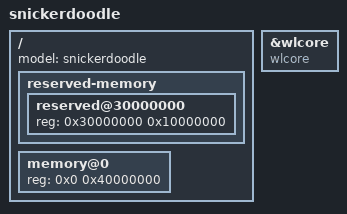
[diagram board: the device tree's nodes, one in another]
/**
 * Copyright (c) 2016 krtkl inc.
 *
 * snickerdoodle base device tree source
 *
 * This program is free software; you can redistribute it and/or modify it
 * under the terms of the GNU General Public License version 2 as published by
 * the Free Software Foundation.
 */

/dts-v1/;
/include/ "snickerdoodle.dtsi"
/include/ "uio.dtsi"

/ {
	model = "snickerdoodle";

	reserved-memory {
		#address-cells = <1>;
		#size-cells = <1>;
		ranges;

		reserved@30000000 {
			reg = <0x30000000 0x10000000>;
		};
	};

	memory@0 {
		device_type = "memory";
		reg = <0x0 0x40000000>;
	};
};

&wlcore {
	compatible = "wlcore", "ti,wl1831";
};

